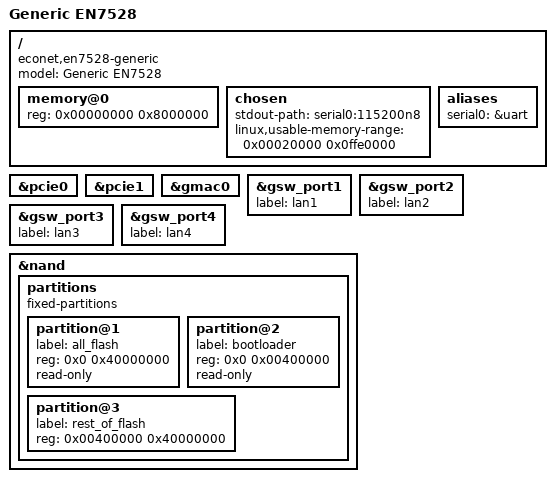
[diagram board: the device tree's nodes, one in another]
// SPDX-License-Identifier: GPL-2.0

/dts-v1/;

#include "en7528.dtsi"

/ {
	model = "Generic EN7528";
	compatible = "econet,en7528-generic", "econet,en7528";

	memory@0 {
		// We hope at least 64MB will be available on every device
		// Increase to at least 128MB for eth switch reg
		device_type = "memory";
		reg = <0x00000000 0x8000000>;
	};

	chosen {
		stdout-path = "serial0:115200n8";
		linux,usable-memory-range = <0x00020000 0x0ffe0000>;
	};

	aliases {
		serial0 = &uart;
	};
};

&pcie0 {
	status = "okay";
};

&pcie1 {
	status = "okay";
};

&gmac0 {
	status = "okay";
};

&gsw_port1 {
	status = "okay";
	label = "lan1";
};

&gsw_port2 {
	status = "okay";
	label = "lan2";
};

&gsw_port3 {
	status = "okay";
	label = "lan3";
};

&gsw_port4 {
	status = "okay";
	label = "lan4";
};

&nand {
	status = "okay";

	partitions {
		compatible = "fixed-partitions";
		#address-cells = <1>;
		#size-cells = <1>;

		partition@1 {
			// We don't know how big the flash is
			// Put 1GB and let it truncate
			label = "all_flash";
			reg = <0x0 0x40000000>;
			read-only;
		};

		partition@2 {
			// We don't know how big the bootloader
			// is, but when we're doing testing, lets
			// make sure nobody touches anything below 4MB
			label = "bootloader";
			reg = <0x0 0x00400000>;
			read-only;
		};

		partition@3 {
			label = "rest_of_flash";
			reg = <0x00400000 0x40000000>;
		};
	};
};
